AUTOSAR XML (schema 4.0)
package /ADAS_Components
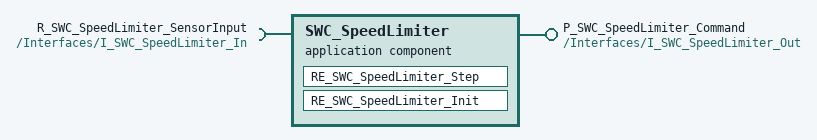
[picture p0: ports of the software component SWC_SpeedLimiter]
  application sw component type SWC_SpeedLimiter  # AUTOSAR Application SWC SWC_SpeedLimiter for ADAS control sub-system
    provide port P_SWC_SpeedLimiter_Command: provided-interface=/Interfaces/I_SWC_SpeedLimiter_Out
    require port R_SWC_SpeedLimiter_SensorInput: required-interface=/Interfaces/I_SWC_SpeedLimiter_In
    behavior SWC_SpeedLimiter_Behavior
      runnable RE_SWC_SpeedLimiter_Step: symbol=SWC_SpeedLimiter_Step
      runnable RE_SWC_SpeedLimiter_Init: symbol=SWC_SpeedLimiter_Init
  sender receiver interface I_SWC_SpeedLimiter_Out  # Sender Receiver Interface for SWC_SpeedLimiter outputs
    data DE_SWC_SpeedLimiter_Signal: type=/AUTOSAR/Platform/uint32
  sender receiver interface I_SWC_SpeedLimiter_In  # Sender Receiver Interface for SWC_SpeedLimiter inputs
    data DE_SWC_SpeedLimiter_RawData: type=/AUTOSAR/Platform/uint16
